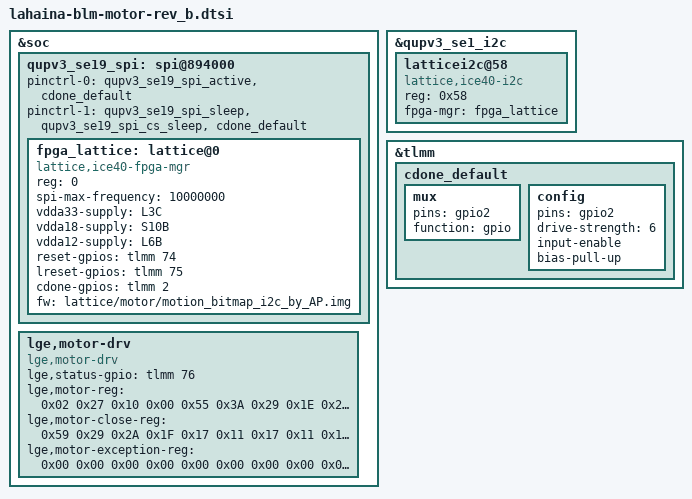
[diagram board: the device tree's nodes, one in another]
&soc {
	/* SPI Download */
	qupv3_se19_spi: spi@894000 {
		pinctrl-names = "default", "sleep";
		pinctrl-0 = <&qupv3_se19_spi_active &cdone_default>;
		pinctrl-1 = <&qupv3_se19_spi_sleep &qupv3_se19_spi_cs_sleep &cdone_default>;

		status = "ok";

		fpga_lattice:lattice@0 {
			compatible = "lattice,ice40-fpga-mgr";
			reg = <0>;
			spi-max-frequency = <10000000>;
			vdda33-supply = <&L3C>;
			vdda18-supply = <&S10B>;
			vdda12-supply = <&L6B>;
			reset-gpios = <&tlmm 74 GPIO_ACTIVE_HIGH>;
			lreset-gpios = <&tlmm 75 GPIO_ACTIVE_HIGH>;
			cdone-gpios = <&tlmm 2 GPIO_ACTIVE_HIGH>;
			fw = "lattice/motor/motion_bitmap_i2c_by_AP.img";
			status = "ok";
		};
	};

	lge,motor-drv {
		compatible = "lge,motor-drv";
		lge,status-gpio = <&tlmm 76 GPIO_ACTIVE_HIGH>; // Enable/Disable check
		lge,motor-reg = /bits/ 8 <
			0x02                                              /* ICE40_R_CTRL         (1) */
			0x27 0x10                                         /* ICE40_R_FH_TIME_CNT  (2) */
			0x00 0x55 0x3A                                    /* ICE40_R_FL_TIME_CNT  (3) */
			0x29 0x1E 0x21 0x17 0x11                          /* ICE40_R_ACC_RATE     (5) */
			0x17 0x1F 0x2A 0x39 0x59                          /* ICE40_R_DEC_RATE     (5) */
			0x00 0x50 0x00 0x50 0x00 0x50 0x00 0x50 0x00 0x50 /* ICE40_R_ACC_CNT     (10) */
			0x00 0x1E 0x00 0x1E 0x00 0x1E 0x00 0x1E 0x00 0x05 /* ICE40_R_DEC_CNT     (10) */
			0x13 0x38                                         /* ICE40_R_TOTAL_PPS    (2) */
			0x88 0x88 0x08                                    /* ICE40_R_DEC_DUTY     (3) */
			0x00 0x00 0x64                                    /* ICE40_R_AUTO_CNT_W   (3) */
			0x00 0x00 0x00                                    /* ICE40_R_AUTO_CNT_REC (3) */
			0x00 0x00                                         /* ICE40_R_CURRENT_PPS  (2) */
			>;
		lge,motor-close-reg = /bits/ 8 <
			0x59 0x29 0x2A 0x1F 0x17                          /* ICE40_R_ACC_RATE     (5) */
			0x11 0x17 0x11 0x1E 0x29                          /* ICE40_R_DEC_RATE     (5) */
			0x00 0x05 0x00 0x1E 0x00 0x1E 0x00 0x1E 0x00 0x1E /* ICE40_R_ACC_CNT     (10) */
			0x00 0x50 0x00 0x50 0x00 0x50 0x00 0x50 0x00 0x50 /* ICE40_R_DEC_CNT     (10) */
			>;
		lge,motor-exception-reg = /bits/ 8 <
			0x00 0x00 0x00 0x00 0x00                          /* ICE40_R_ACC_RATE     (5) */
			0x00 0x00 0x00 0x00 0x00                          /* ICE40_R_DEC_RATE     (5) */
			0x00 0x01 0x00 0x01 0x00 0x01 0x00 0x01 0x00 0x01 /* ICE40_R_ACC_CNT     (10) */
			0x00 0x01 0x00 0x01 0x00 0x01 0x00 0x01 0x00 0x01 /* ICE40_R_DEC_CNT     (10) */
			>;
		status = "ok";
	};
};

&qupv3_se1_i2c {
	status = "ok";

	latticei2c@58 {
		compatible = "lattice,ice40-i2c";
		reg = <0x58>;
		fpga-mgr = <&fpga_lattice>;
		status = "ok";
	};
};

&tlmm {
	cdone_default:cdone_default {
		mux {
			pins = "gpio2";
			function = "gpio";
		};

		config {
			pins = "gpio2";
			drive-strength = <6>;
			input-enable;
			bias-pull-up;
		};
	};
};
